AUTOSAR XML (schema 4-0-3)
package /ComponentTypes
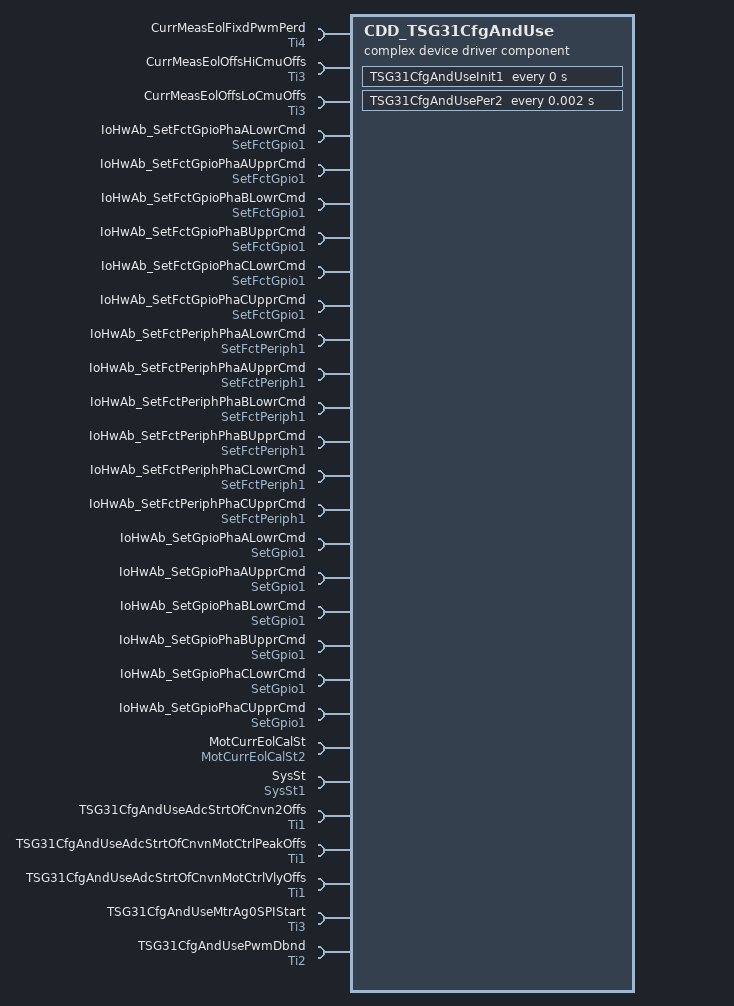
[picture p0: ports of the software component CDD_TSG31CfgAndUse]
  complex device driver sw component type CDD_TSG31CfgAndUse
    28 x require port:
      CurrMeasEolFixdPwmPerd: parameter-require-com-spec{init-value=62500, parameter=Val}, required-interface=Ti4
      CurrMeasEolOffsHiCmuOffs: parameter-require-com-spec{init-value=50000, parameter=Val}, required-interface=Ti3
      CurrMeasEolOffsLoCmuOffs: parameter-require-com-spec{init-value=6250, parameter=Val}, required-interface=Ti3
      IoHwAb_SetFctGpioPhaALowrCmd: required-interface=SetFctGpio1
      IoHwAb_SetFctGpioPhaAUpprCmd: required-interface=SetFctGpio1
      IoHwAb_SetFctGpioPhaBLowrCmd: required-interface=SetFctGpio1
      IoHwAb_SetFctGpioPhaBUpprCmd: required-interface=SetFctGpio1
      IoHwAb_SetFctGpioPhaCLowrCmd: required-interface=SetFctGpio1
      IoHwAb_SetFctGpioPhaCUpprCmd: required-interface=SetFctGpio1
      IoHwAb_SetFctPeriphPhaALowrCmd: required-interface=SetFctPeriph1
      IoHwAb_SetFctPeriphPhaAUpprCmd: required-interface=SetFctPeriph1
      IoHwAb_SetFctPeriphPhaBLowrCmd: required-interface=SetFctPeriph1
      IoHwAb_SetFctPeriphPhaBUpprCmd: required-interface=SetFctPeriph1
      IoHwAb_SetFctPeriphPhaCLowrCmd: required-interface=SetFctPeriph1
      IoHwAb_SetFctPeriphPhaCUpprCmd: required-interface=SetFctPeriph1
      IoHwAb_SetGpioPhaALowrCmd: required-interface=SetGpio1
      IoHwAb_SetGpioPhaAUpprCmd: required-interface=SetGpio1
      IoHwAb_SetGpioPhaBLowrCmd: required-interface=SetGpio1
      IoHwAb_SetGpioPhaBUpprCmd: required-interface=SetGpio1
      IoHwAb_SetGpioPhaCLowrCmd: required-interface=SetGpio1
      IoHwAb_SetGpioPhaCUpprCmd: required-interface=SetGpio1
      MotCurrEolCalSt: nonqueued-receiver-com-spec{data-element=Val, filter=data-filter-type=ALWAYS, init-value=0}, required-interface=MotCurrEolCalSt2
      SysSt: nonqueued-receiver-com-spec{data-element=Val, filter=data-filter-type=ALWAYS, init-value=3}, required-interface=SysSt1
      TSG31CfgAndUseAdcStrtOfCnvn2Offs: parameter-require-com-spec{init-value=5000, parameter=Val}, required-interface=Ti1
      TSG31CfgAndUseAdcStrtOfCnvnMotCtrlPeakOffs: parameter-require-com-spec{init-value=6000, parameter=Val}, required-interface=Ti1
      TSG31CfgAndUseAdcStrtOfCnvnMotCtrlVlyOffs: parameter-require-com-spec{init-value=7000, parameter=Val}, required-interface=Ti1
      TSG31CfgAndUseMtrAg0SPIStart: parameter-require-com-spec{init-value=1000, parameter=Val}, required-interface=Ti3
      TSG31CfgAndUsePwmDbnd: parameter-require-com-spec{init-value=200, parameter=Val}, required-interface=Ti2
    behavior CDD_TSG31CfgAndUse_InternalBehavior: data-type-mapping=Nexteer
      ar-typed-per-instance-memorys:
        data TSG31CfgAndUseAdcStrtOfCnvnPeak: sw-calibration-access=READ-ONLY, type=Cnt8
        data TSG31CfgAndUseMotAg0SPIStart: sw-calibration-access=READ-ONLY, type=Cnt8
        data TSG31CfgAndUseSysStEnaPrev: sw-calibration-access=READ-ONLY, type=boolean
      timing event CDD_TSG31CfgAndUse_InitEvent: start-on-event=TSG31CfgAndUseInit1, period=0
      timing event TMT_TSG31CfgAndUsePer2: start-on-event=TSG31CfgAndUsePer2, period=0.002
      runnable TSG31CfgAndUseInit1
        12 x sync call, all with timeout=0:
          SC_IoHwAb_SetFctGpioPhaALowrCmd_Oper: operation=IoHwAb_SetFctGpioPhaALowrCmd.Oper
          SC_IoHwAb_SetFctGpioPhaAUpprCmd_Oper: operation=IoHwAb_SetFctGpioPhaAUpprCmd.Oper
          SC_IoHwAb_SetFctGpioPhaBLowrCmd_Oper: operation=IoHwAb_SetFctGpioPhaBLowrCmd.Oper
          SC_IoHwAb_SetFctGpioPhaBUpprCmd_Oper: operation=IoHwAb_SetFctGpioPhaBUpprCmd.Oper
          SC_IoHwAb_SetFctGpioPhaCLowrCmd_Oper: operation=IoHwAb_SetFctGpioPhaCLowrCmd.Oper
          SC_IoHwAb_SetFctGpioPhaCUpprCmd_Oper: operation=IoHwAb_SetFctGpioPhaCUpprCmd.Oper
          SC_IoHwAb_SetGpioPhaALowrCmd_Oper: operation=IoHwAb_SetGpioPhaALowrCmd.Oper
          SC_IoHwAb_SetGpioPhaAUpprCmd_Oper: operation=IoHwAb_SetGpioPhaAUpprCmd.Oper
          SC_IoHwAb_SetGpioPhaBLowrCmd_Oper: operation=IoHwAb_SetGpioPhaBLowrCmd.Oper
          SC_IoHwAb_SetGpioPhaBUpprCmd_Oper: operation=IoHwAb_SetGpioPhaBUpprCmd.Oper
          SC_IoHwAb_SetGpioPhaCLowrCmd_Oper: operation=IoHwAb_SetGpioPhaCLowrCmd.Oper
          SC_IoHwAb_SetGpioPhaCUpprCmd_Oper: operation=IoHwAb_SetGpioPhaCUpprCmd.Oper
      runnable TSG31CfgAndUsePer2
        data-receive-point-by-arguments:
          access REC_MotCurrEolCalSt_Val: accessed-variable=MotCurrEolCalSt.Val
          access REC_SysSt_Val: accessed-variable=SysSt.Val
        18 x sync call, all with timeout=0:
          SC_IoHwAb_SetFctGpioPhaALowrCmd_Oper: operation=IoHwAb_SetFctGpioPhaALowrCmd.Oper
          SC_IoHwAb_SetFctGpioPhaAUpprCmd_Oper: operation=IoHwAb_SetFctGpioPhaAUpprCmd.Oper
          SC_IoHwAb_SetFctGpioPhaBLowrCmd_Oper: operation=IoHwAb_SetFctGpioPhaBLowrCmd.Oper
          SC_IoHwAb_SetFctGpioPhaBUpprCmd_Oper: operation=IoHwAb_SetFctGpioPhaBUpprCmd.Oper
          SC_IoHwAb_SetFctGpioPhaCLowrCmd_Oper: operation=IoHwAb_SetFctGpioPhaCLowrCmd.Oper
          SC_IoHwAb_SetFctGpioPhaCUpprCmd_Oper: operation=IoHwAb_SetFctGpioPhaCUpprCmd.Oper
          SC_IoHwAb_SetFctPeriphPhaALowrCmd_Oper: operation=IoHwAb_SetFctPeriphPhaALowrCmd.Oper
          SC_IoHwAb_SetFctPeriphPhaAUpprCmd_Oper: operation=IoHwAb_SetFctPeriphPhaAUpprCmd.Oper
          SC_IoHwAb_SetFctPeriphPhaBLowrCmd_Oper: operation=IoHwAb_SetFctPeriphPhaBLowrCmd.Oper
          SC_IoHwAb_SetFctPeriphPhaBUpprCmd_Oper: operation=IoHwAb_SetFctPeriphPhaBUpprCmd.Oper
          SC_IoHwAb_SetFctPeriphPhaCLowrCmd_Oper: operation=IoHwAb_SetFctPeriphPhaCLowrCmd.Oper
          SC_IoHwAb_SetFctPeriphPhaCUpprCmd_Oper: operation=IoHwAb_SetFctPeriphPhaCUpprCmd.Oper
          SC_IoHwAb_SetGpioPhaALowrCmd_Oper: operation=IoHwAb_SetGpioPhaALowrCmd.Oper
          SC_IoHwAb_SetGpioPhaAUpprCmd_Oper: operation=IoHwAb_SetGpioPhaAUpprCmd.Oper
          SC_IoHwAb_SetGpioPhaBLowrCmd_Oper: operation=IoHwAb_SetGpioPhaBLowrCmd.Oper
          SC_IoHwAb_SetGpioPhaBUpprCmd_Oper: operation=IoHwAb_SetGpioPhaBUpprCmd.Oper
          SC_IoHwAb_SetGpioPhaCLowrCmd_Oper: operation=IoHwAb_SetGpioPhaCLowrCmd.Oper
          SC_IoHwAb_SetGpioPhaCUpprCmd_Oper: operation=IoHwAb_SetGpioPhaCUpprCmd.Oper
  swc implementation CDD_TSG31CfgAndUse_Implementation: behavior=CDD_TSG31CfgAndUse_InternalBehavior
    code-descriptors:
      code Default: artifact-descriptors=autosar-engineering-object={short-label=Default, category=SWSRC}
